VERSION "Car_DBC_Example"

NS_ :

BS_:

BU_: ECU_ENGINE ECU_BRAKE ECU_DASH

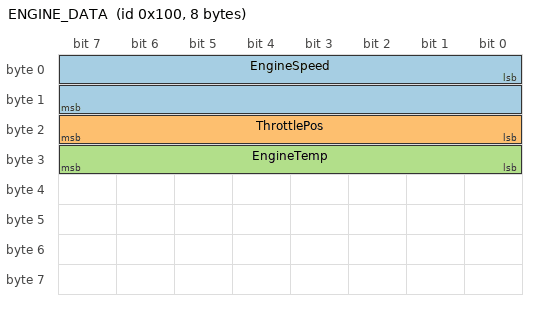
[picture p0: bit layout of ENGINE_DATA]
BO_ 256 ENGINE_DATA: 8 ECU_ENGINE
 SG_ EngineSpeed : 0|16@1+ (0.125,0) [0|8000] "rpm" ECU_DASH
 SG_ ThrottlePos : 16|8@1+ (0.4,0) [0|100] "%" ECU_DASH
 SG_ EngineTemp  : 24|8@1+ (1,-40) [-40|215] "C" ECU_DASH

BO_ 257 VEHICLE_SPEED: 8 ECU_ENGINE
 SG_ VehicleSpeed : 0|16@1+ (0.01,0) [0|250] "km/h" ECU_DASH

BO_ 300 BRAKE_DATA: 8 ECU_BRAKE
 SG_ BrakePressure : 0|16@1+ (0.1,0) [0|100] "bar" ECU_DASH
 SG_ ABS_Active    : 16|1@1+ (1,0) [0|1] "" ECU_DASH
